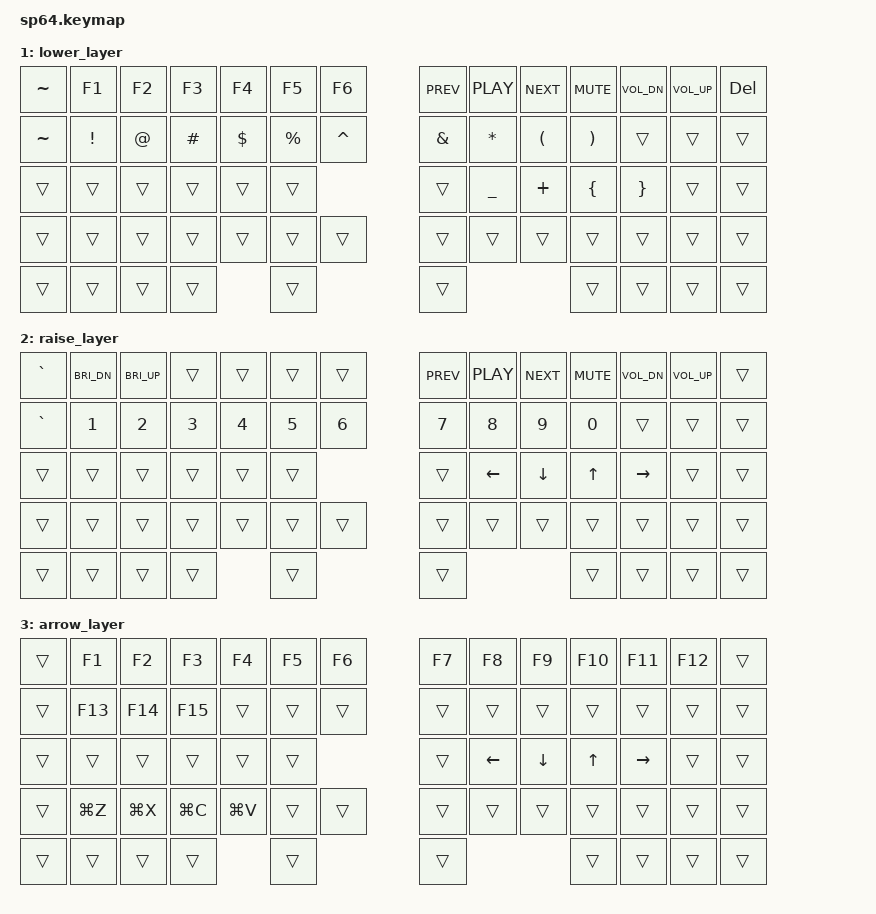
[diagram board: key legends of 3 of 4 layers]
/*
 * Copyright (c) 2020 The ZMK Contributors
 *
 * SPDX-License-Identifier: MIT
 */


#include <behaviors.dtsi>
#include <dt-bindings/zmk/outputs.h>
#include <dt-bindings/zmk/keys.h>
#include <dt-bindings/zmk/bt.h>


/ {
	behaviors {
        hm: homerow_mods {
            compatible = "zmk,behavior-hold-tap";
            label = "HOMEROW_MODS";
            #binding-cells = <2>;
            tapping_term_ms = <150>;
            quick_tap_ms = <0>;
            flavor = "tap-preferred";
            bindings = <&kp>, <&kp>;
        };
		sm: shift_mod {
            compatible = "zmk,behavior-hold-tap";
            label = "SHIFT_MODS";
            #binding-cells = <2>;
            tapping_term_ms = <120>;
            quick_tap_ms = <0>;
            flavor = "balanced";
            bindings = <&kp>, <&kp>;
        };
		// custom layer tap because &lt did not work very well for me
		lm: layer_mods {
			compatible = "zmk,behavior-hold-tap";
			label = "LAYER_MODS";
			#binding-cells = <2>;
			tapping_term_ms = <200>;
			quick_tap_ms = <0>;
			flavor = "hold-preferred";
			bindings = <&mo>, <&kp>;
		};
    };
	keymap {
		compatible = "zmk,keymap";

		default_layer {
// RC(0,0) RC(0,1) RC(0,2) RC(0,3) RC(0,4) RC(0,5) RC(0,6)         RC(0,7) RC(0,8) RC(0,9) RC(0,10) RC(0,11) RC(0,12)          RC(0,14)
// RC(1,0) RC(1,1) RC(1,2) RC(1,3) RC(1,4) RC(1,5)                 RC(1,7) RC(1,8) RC(1,9) RC(1,10) RC(1,11) RC(1,12) RC(1,13) RC(1,14)
// RC(2,0) RC(2,1) RC(2,2) RC(2,3) RC(2,4) RC(2,5)                 RC(2,7) RC(2,8) RC(2,9) RC(2,10) RC(2,11) RC(2,12)          RC(2,14)
// RC(3,0) RC(3,1) RC(3,2) RC(3,3) RC(3,4) RC(3,5)                 RC(3,7) RC(3,8) RC(3,9) RC(3,10) RC(3,11) RC(3,13) RC(3,13) RC(3,14)
// RC(4,0) RC(4,1) RC(4,2) RC(4,3)         RC(4,5)                 RC(4,7)                 RC(4,10) RC(4,11) RC(4,13) RC(4,13) RC(4,14)
			bindings = <
&kp ESCAPE &kp NUMBER_1 &kp NUMBER_2 &kp NUMBER_3 &kp NUMBER_4 &kp NUMBER_5 &kp NUMBER_6                  &kp NUMBER_7 &kp NUMBER_8 &kp NUMBER_9 &kp NUMBER_0 &kp MINUS &kp EQUAL                 &kp BACKSPACE
&kp TAB    &kp Q        &kp W        &kp E        &kp R        &kp T                                      &kp Y        &kp U        &kp I        &kp O        &kp P     &kp LBKT     &kp RBKT     &kp BACKSLASH
&kp CAPS   &kp A        &kp S        &kp D        &kp F        &kp G                                      &kp H        &kp J        &kp K        &kp L        &kp SEMI  &kp APOS                  &kp RETURN
&kp LEFT_SHIFT &kp Z    &kp X        &kp C        &kp V        &kp B                                      &kp N        &kp M        &kp COMMA    &kp PERIOD   &kp SLASH &kp RSHFT    &kp UP       &kp C_PLAY
&mo 3      &mo 1        &kp SPACE    &kp LALT                  &kp LGUI                                   &lt 2 SPACE                            &kp RGUI     &kp RALT  &kp LEFT     &kp DOWN     &kp RIGHT
			>;
		};
		lower_layer {
			bindings = <
&kp TILDE  &kp F1       &kp F2       &kp F3       &kp F4       &kp F5       &kp F6                        &kp C_PREV   &kp C_PLAY   &kp C_NEXT   &kp C_MUTE   &kp C_VOL_DN &kp C_VOL_UP                  &kp DELETE    
&kp TILDE  &kp EXCL     &kp AT       &kp HASH     &kp DLLR     &kp PRCNT                                  &kp CARET    &kp AMPS     &kp STAR     &kp LPAR     &kp RPAR     &trans        &trans          &trans   
&trans     &trans       &trans       &trans       &trans       &trans                                     &trans       &kp UNDER    &kp PLUS     &kp LBRC     &kp RBRC     &trans                        &trans   
&trans     &trans       &trans       &trans       &trans       &trans                                     &trans       &trans       &trans       &trans       &trans       &trans        &trans          &trans   
&trans     &trans       &trans       &trans                    &trans                                     &trans                                 &trans       &trans       &trans                        &trans    
			>;
		};
		raise_layer {
			bindings = <
&kp GRAVE  &kp C_BRI_DN &kp C_BRI_UP &trans       &trans       &trans       &trans                        &kp C_PREV   &kp C_PLAY   &kp C_NEXT   &kp C_MUTE   &kp C_VOL_DN &kp C_VOL_UP                  &trans       
&kp GRAVE  &kp NUMBER_1 &kp NUMBER_2 &kp NUMBER_3 &kp NUMBER_4 &kp NUMBER_5                               &kp NUMBER_6 &kp NUMBER_7 &kp NUMBER_8 &kp NUMBER_9 &kp NUMBER_0 &trans        &trans          &trans   
&trans     &trans       &trans       &trans       &trans       &trans                                     &trans       &kp LEFT     &kp DOWN     &kp UP       &kp RIGHT    &trans                        &trans   
&trans     &trans       &trans       &trans       &trans       &trans                                     &trans       &trans       &trans       &trans       &trans       &trans        &trans          &trans   
&trans     &trans       &trans       &trans                    &trans                                     &trans                                 &trans       &trans       &trans                        &trans    
			>;
		};

		arrow_layer {
			bindings = <
&trans     &kp F1       &kp F2       &kp F3       &kp F4       &kp F5       &kp F6                        &kp F7       &kp F8       &kp F9       &kp F10      &kp F11      &kp F12                       &trans       
&trans     &kp F13      &kp F14      &kp F15      &trans       &trans                                     &trans       &trans       &trans       &trans       &trans       &trans        &trans          &trans   
&trans     &trans       &trans       &trans       &trans       &trans                                     &trans       &kp LEFT     &kp DOWN     &kp UP       &kp RIGHT    &trans                        &trans   
&trans     &kp LG(Z)    &kp LG(X)    &kp LG(C)    &kp LG(V)    &trans                                     &trans       &trans       &trans       &trans       &trans       &trans        &trans          &trans   
&trans     &trans       &trans       &trans                    &trans                                     &trans                                 &trans       &trans       &trans                        &trans    
			>;
		};
	};
};
